# STM32U5A9 register map
File version: 1.0
CPU: CM33 r0p1, little endian, MPU, FPU, 4 interrupt priority bits
Registers are 32-bit, read-write, reset 0x0 unless marked. A register's access mark holds for its fields unless they carry their own. Offsets are from the block's base; [hi:lo] are bit positions; 'fields as' and 'values as' point back to an identical list.

## CORDIC — CORDIC Co-processor
Base 0x40021000
Same registers: SEC_CORDIC 0x50021000
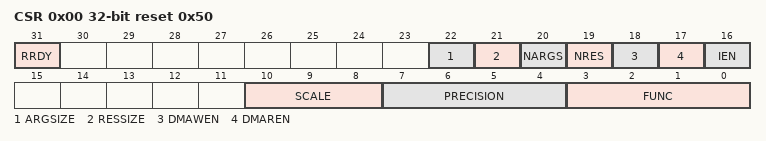
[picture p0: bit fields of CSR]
0x00 CSR access per field reset 0x50 — CORDIC Control Status register
  [31] RRDY ro — Result ready flag
  [22] ARGSIZE rw — Width of input data
  [21] RESSIZE rw — Width of output data
  [20] NARGS rw — Number of arguments expected by the CORDIC_WDATA register
  [19] NRES rw — Number of results in the CORDIC_RDATA register
  [18] DMAWEN rw — Enable DMA write channel
  [17] DMAREN rw — Enable DMA read channel
  [16] IEN rw — Enable interrupt
  [10:8] SCALE rw — Scaling factor
  [7:4] PRECISION rw — Precision required (number of iterations)
  [3:0] FUNC rw — Function
0x04 WDATA wo — FMAC Write Data register
  [31:0] ARG — Function input arguments
0x08 RDATA ro — FMAC Read Data register
  [31:0] RES — Function result

## CRC — Cyclic redundancy check calculation unit
Base 0x40023000
Same registers: SEC_CRC 0x50023000
0x00 DR reset 0xFFFFFFFF — Data register
  [31:0] DR — Data register bits
0x00 DR8 8-bit reset 0xFF (alternate view of DR) — Data register - byte sized
  [7:0] DR8 — Data register bits
0x00 DR16 16-bit reset 0xFFFF (alternate view of DR) — Data register - half-word sized
  [15:0] DR16 — Data register bits
0x04 IDR — Independent data register
  [31:0] IDR — General-purpose 8-bit data register bits
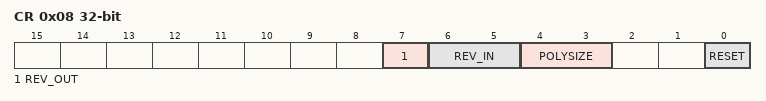
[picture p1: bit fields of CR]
0x08 CR — Control register
  [7] REV_OUT — Reverse output data
    0=Normal (Bit order not affected); 1=Reversed (Bit reversed output)
  [6:5] REV_IN — Reverse input data
    0=Normal (Bit order not affected); 1=Byte (Bit reversal done by byte); 2=HalfWord (Bit reversal done by half-word); 3=Word (Bit reversal done by word)
  [4:3] POLYSIZE — Polynomial size
    0=32-bit polynomial; 1=16-bit polynomial; 2=8-bit polynomial; 3=7-bit polynomial
  [0] RESET — RESET bit
    on write: 1=Resets the CRC calculation unit and sets the data register to 0xFFFF FFFF
0x10 INIT reset 0xFFFFFFFF — Initial CRC value
  [31:0] INIT — Programmable initial CRC value
0x14 POL reset 0x4C11DB7 — polynomial
  [31:0] POL — Programmable polynomial

## CRS — Clock recovery system
Base 0x40006000
Same registers: SEC_CRS 0x50006000
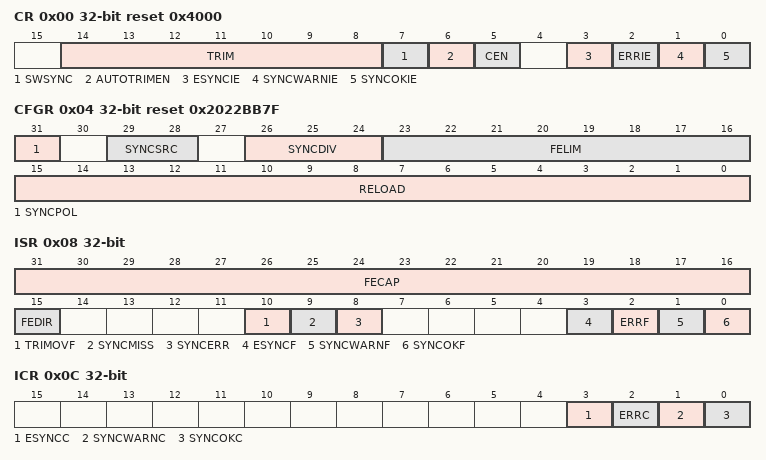
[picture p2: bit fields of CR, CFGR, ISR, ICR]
0x00 CR reset 0x4000 — control register
  [14:8] TRIM range 0..63 — HSI48 oscillator smooth trimming
  [7] SWSYNC — Generate software SYNC event
    1=Sync (A software sync is generated)
  [6] AUTOTRIMEN — Automatic trimming enable
    0=Disabled (Automatic trimming disabled); 1=Enabled (Automatic trimming enabled)
  [5] CEN — Frequency error counter enable
    0=Disabled (Frequency error counter disabled); 1=Enabled (Frequency error counter enabled)
  [3] ESYNCIE — Expected SYNC interrupt enable
    0=Disabled (Interrupt disabled); 1=Enabled (Interrupt enabled)
  [2] ERRIE — Synchronization or trimming error interrupt enable
    values as ESYNCIE
  [1] SYNCWARNIE — SYNC warning interrupt enable
    values as ESYNCIE
  [0] SYNCOKIE — SYNC event OK interrupt enable
    values as ESYNCIE
0x04 CFGR reset 0x2022BB7F — configuration register
  [31] SYNCPOL — SYNC polarity selection
    0=RisingEdge (SYNC active on rising edge); 1=FallingEdge (SYNC active on falling edge)
  [29:28] SYNCSRC — SYNC signal source selection
    0=GPIO_AF (GPIO AF (crs_sync_in_1) selected as SYNC signal source); 1=LSE (LSE (crs_sync_in_2) selected as SYNC signal source); 2=USB_SOF (USB SOF (crs_sync_in_3) selected as SYNC signal source)
  [26:24] SYNCDIV — SYNC divider
    0=Div1 (SYNC not divided); 1=Div2 (SYNC divided by 2); 2=Div4 (SYNC divided by 4); 3=Div8 (SYNC divided by 8); 4=Div16 (SYNC divided by 16); 5=Div32 (SYNC divided by 32); 6=Div64 (SYNC divided by 64); 7=Div128 (SYNC divided by 128)
  [23:16] FELIM — Frequency error limit
  [15:0] RELOAD — Counter reload value
0x08 ISR ro — interrupt and status register
  [31:16] FECAP — Frequency error capture
  [15] FEDIR — Frequency error direction
    0=UpCounting (Error in up-counting direction); 1=DownCounting (Error in down-counting direction)
  [10] TRIMOVF — Trimming overflow or underflow
    0=NotSignaled (Signal not set); 1=Signaled (Signal set)
  [9] SYNCMISS — SYNC missed
    0=NotSignaled (Signal not set); 1=Signaled (Signal set)
  [8] SYNCERR — SYNC error
    0=NotSignaled (Signal not set); 1=Signaled (Signal set)
  [3] ESYNCF — Expected SYNC flag
    0=NotSignaled (Signal not set); 1=Signaled (Signal set)
  [2] ERRF — Error flag
    0=NotSignaled (Signal not set); 1=Signaled (Signal set)
  [1] SYNCWARNF — SYNC warning flag
    0=NotSignaled (Signal not set); 1=Signaled (Signal set)
  [0] SYNCOKF — SYNC event OK flag
    0=NotSignaled (Signal not set); 1=Signaled (Signal set)
0x0C ICR — interrupt flag clear register
  [all] fields
    1=Clear flag
  [3] ESYNCC — Expected SYNC clear flag
  [2] ERRC — Error clear flag
  [1] SYNCWARNC — SYNC warning clear flag
  [0] SYNCOKC — SYNC event OK clear flag
